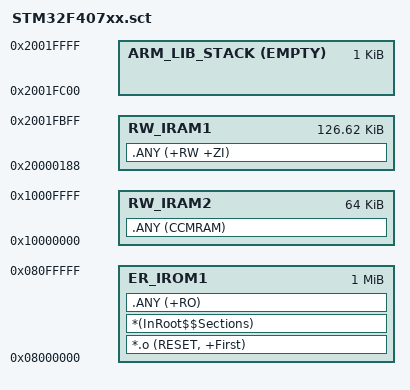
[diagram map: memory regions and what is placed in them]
#! armcc -E
; *****************************************
; *** Scatter-Loading Description File  ***
; *****************************************

#if !defined(MBED_BOOT_STACK_SIZE)
  #define MBED_BOOT_STACK_SIZE 0x400
#endif

#define Stack_Size MBED_BOOT_STACK_SIZE

LR_IROM1 0x08000000 0x00100000  {    ; load region size_region
  ER_IROM1 0x08000000 0x00100000  {  ; load address = execution address
   *.o (RESET, +First)
   *(InRoot$$Sections)
   .ANY (+RO)
  }
  RW_IRAM1 0x20000188 0x0001FE78-Stack_Size {
   .ANY (+RW +ZI)
  }
  RW_IRAM2 0x10000000 0x00010000  {  ; CCM
   .ANY (CCMRAM)
  }
  ARM_LIB_STACK (0x20000188+0x0001FE78) EMPTY -Stack_Size { ; stack
  }
}

